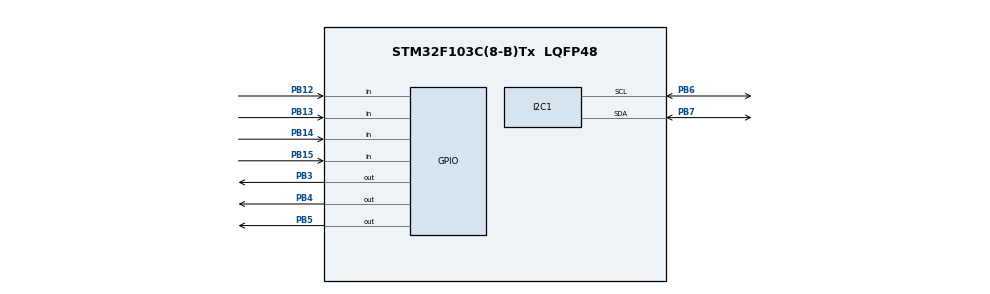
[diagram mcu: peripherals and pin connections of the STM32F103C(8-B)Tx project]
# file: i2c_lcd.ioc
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Mcu.Family=STM32F1
Mcu.Name=STM32F103C(8-B)Tx
Mcu.Package=LQFP48
NVIC.PriorityGroup=NVIC_PRIORITYGROUP_4
PA13.Mode=Serial_Wire
PA13.Signal=SYS_JTMS-SWDIO
PA14.Mode=Serial_Wire
PA14.Signal=SYS_JTCK-SWCLK
PB12.Signal=GPIO_Input
PB13.Signal=GPIO_Input
PB14.Signal=GPIO_Input
PB15.GPIO_Mode=GPIO_MODE_INPUT
PB15.Signal=GPIO_Input
PB3.Signal=GPIO_Output
PB4.Signal=GPIO_Output
PB5.Signal=GPIO_Output
PB6.Mode=I2C
PB6.Signal=I2C1_SCL
PB7.Mode=I2C
PB7.Signal=I2C1_SDA
PD0-OSC_IN.Mode=HSE-External-Oscillator
PD0-OSC_IN.Signal=RCC_OSC_IN
PD1-OSC_OUT.Mode=HSE-External-Oscillator
PD1-OSC_OUT.Signal=RCC_OSC_OUT
ProjectManager.HeapSize=0x200
ProjectManager.StackSize=0x400
ProjectManager.TargetToolchain=STM32CubeIDE
RCC.AHBFreq_Value=48000000
RCC.APB1CLKDivider=RCC_HCLK_DIV2
RCC.APB1Freq_Value=24000000
RCC.APB1TimFreq_Value=48000000
RCC.APB2Freq_Value=48000000
RCC.APB2TimFreq_Value=48000000
RCC.HCLKFreq_Value=48000000
RCC.PLLMUL=RCC_PLL_MUL12
RCC.SYSCLKFreq_VALUE=48000000
RCC.SYSCLKSource=RCC_SYSCLKSOURCE_PLLCLK
RCC.USBFreq_Value=48000000
board=custom

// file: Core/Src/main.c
/* USER CODE BEGIN Header */
/**
  ******************************************************************************
  * @file           : main.c
  * @brief          : Main program body
  ******************************************************************************
  * @attention
  *
  * Copyright (c) 2025 STMicroelectronics.
  * All rights reserved.
  *
  * This software is licensed under terms that can be found in the LICENSE file
  * in the root directory of this software component.
  * If no LICENSE file comes with this software, it is provided AS-IS.
  *
  ******************************************************************************
  */
/* USER CODE END Header */
#include "main.h"

/* USER CODE BEGIN Includes */
#include "i2c.h"
#include "kp.h"
/* USER CODE END Includes */

I2C_HandleTypeDef hi2c1;

void SystemClock_Config(void);
static void MX_GPIO_Init(void);
static void MX_I2C1_Init(void);

/* USER CODE BEGIN 0 */

volatile uint8_t key_current = 0;
volatile uint8_t key_last = 0;

/* USER CODE END 0 */

int main(void)
{

  /* MCU Configuration--------------------------------------------------------*/

  /* Reset of all peripherals, Initializes the Flash interface and the Systick. */
  HAL_Init();

  /* Configure the system clock */
  SystemClock_Config();

  /* Initialize all configured peripherals */
  MX_GPIO_Init();
  MX_I2C1_Init();
  /* USER CODE BEGIN 2 */
LCD_Init();
LCD_Write_CMD(0x0E); //hien con tro
LCD_Clear();

  /* USER CODE END 2 */

  /* Infinite loop */
  /* USER CODE BEGIN WHILE */
  while (1)
  {
	  key_current = Keypad_Getkey();
	  Keypad_handle();
    /* USER CODE END WHILE */

  }
}

void SystemClock_Config(void)
{
  LL_FLASH_SetLatency(LL_FLASH_LATENCY_1);
  while(LL_FLASH_GetLatency()!= LL_FLASH_LATENCY_1)
  {
  }
  LL_RCC_HSI_SetCalibTrimming(16);
  LL_RCC_HSI_Enable();

   /* Wait till HSI is ready */
  while(LL_RCC_HSI_IsReady() != 1)
  {

  }
  LL_RCC_PLL_ConfigDomain_SYS(LL_RCC_PLLSOURCE_HSI_DIV_2, LL_RCC_PLL_MUL_12);
  LL_RCC_PLL_Enable();

   /* Wait till PLL is ready */
  while(LL_RCC_PLL_IsReady() != 1)
  {

  }
  LL_RCC_SetAHBPrescaler(LL_RCC_SYSCLK_DIV_1);
  LL_RCC_SetAPB1Prescaler(LL_RCC_APB1_DIV_2);
  LL_RCC_SetAPB2Prescaler(LL_RCC_APB2_DIV_1);
  LL_RCC_SetSysClkSource(LL_RCC_SYS_CLKSOURCE_PLL);

   /* Wait till System clock is ready */
  while(LL_RCC_GetSysClkSource() != LL_RCC_SYS_CLKSOURCE_STATUS_PLL)
  {

  }
  LL_SetSystemCoreClock(48000000);

   /* Update the time base */
  if (HAL_InitTick (TICK_INT_PRIORITY) != HAL_OK)
  {
    Error_Handler();
  }
}

static void MX_I2C1_Init(void)
{

  hi2c1.Instance = I2C1;
  hi2c1.Init.ClockSpeed = 100000;
  hi2c1.Init.DutyCycle = I2C_DUTYCYCLE_2;
  hi2c1.Init.OwnAddress1 = 0;
  hi2c1.Init.AddressingMode = I2C_ADDRESSINGMODE_7BIT;
  hi2c1.Init.DualAddressMode = I2C_DUALADDRESS_DISABLE;
  hi2c1.Init.OwnAddress2 = 0;
  hi2c1.Init.GeneralCallMode = I2C_GENERALCALL_DISABLE;
  hi2c1.Init.NoStretchMode = I2C_NOSTRETCH_DISABLE;
  if (HAL_I2C_Init(&hi2c1) != HAL_OK)
  {
    Error_Handler();
  }

}

static void MX_GPIO_Init(void)
{
  LL_GPIO_InitTypeDef GPIO_InitStruct = {0};

  /* GPIO Ports Clock Enable */
  LL_APB2_GRP1_EnableClock(LL_APB2_GRP1_PERIPH_GPIOD);
  LL_APB2_GRP1_EnableClock(LL_APB2_GRP1_PERIPH_GPIOB);
  LL_APB2_GRP1_EnableClock(LL_APB2_GRP1_PERIPH_GPIOA);

  /**/
  LL_GPIO_ResetOutputPin(GPIOB, LL_GPIO_PIN_3|LL_GPIO_PIN_4|LL_GPIO_PIN_5);

  /**/
  GPIO_InitStruct.Pin = LL_GPIO_PIN_12|LL_GPIO_PIN_13|LL_GPIO_PIN_14|LL_GPIO_PIN_15;
  GPIO_InitStruct.Mode = LL_GPIO_MODE_FLOATING;
  LL_GPIO_Init(GPIOB, &GPIO_InitStruct);

  /**/
  GPIO_InitStruct.Pin = LL_GPIO_PIN_3|LL_GPIO_PIN_4|LL_GPIO_PIN_5;
  GPIO_InitStruct.Mode = LL_GPIO_MODE_OUTPUT;
  GPIO_InitStruct.Speed = LL_GPIO_SPEED_FREQ_LOW;
  GPIO_InitStruct.OutputType = LL_GPIO_OUTPUT_PUSHPULL;
  LL_GPIO_Init(GPIOB, &GPIO_InitStruct);

}

void Error_Handler(void)
{
  __disable_irq();
  while (1)
  {
  }
}
